AUTOSAR XML (schema 314)
package /ComponentType
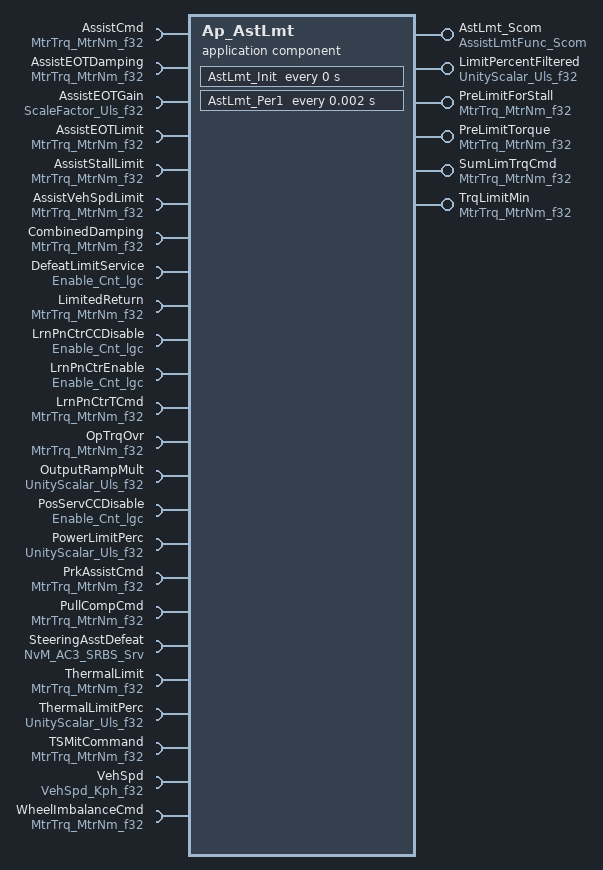
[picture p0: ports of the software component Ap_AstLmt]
  application software component type Ap_AstLmt
    6 x provide port:
      AstLmt_Scom: provided-interface=AssistLmtFunc_Scom
        provided-com-specs:
          operation=GetSteeringAssistDefeat, queue-length=1
          operation=ManualTrqCmd, queue-length=1
          operation=SetSteeringAssistDefeat, queue-length=1
      LimitPercentFiltered: unqueued-sender-com-spec{data-element=Uls_f32, can-invalidate=false, init-value=D_ZERO_ULS_F32}, provided-interface=UnityScalar_Uls_f32
      PreLimitForStall: unqueued-sender-com-spec{data-element=MtrNm_f32, can-invalidate=false, init-value=D_ZERO_ULS_F32}, provided-interface=MtrTrq_MtrNm_f32
      PreLimitTorque: unqueued-sender-com-spec{data-element=MtrNm_f32, can-invalidate=false, init-value=D_ZERO_ULS_F32}, provided-interface=MtrTrq_MtrNm_f32
      SumLimTrqCmd: unqueued-sender-com-spec{data-element=MtrNm_f32, can-invalidate=false, init-value=D_ZERO_ULS_F32}, provided-interface=MtrTrq_MtrNm_f32
      TrqLimitMin: unqueued-sender-com-spec{data-element=MtrNm_f32, can-invalidate=false, init-value=D_ZERO_ULS_F32}, provided-interface=MtrTrq_MtrNm_f32
    24 x require port:
      AssistCmd: unqueued-receiver-com-spec{data-element=MtrNm_f32, init-value=D_ZERO_ULS_F32}, required-interface=MtrTrq_MtrNm_f32
      AssistEOTDamping: unqueued-receiver-com-spec{data-element=MtrNm_f32, init-value=D_ZERO_ULS_F32}, required-interface=MtrTrq_MtrNm_f32
      AssistEOTGain: unqueued-receiver-com-spec{data-element=Uls_f32, init-value=D_ONE_ULS_F32}, required-interface=ScaleFactor_Uls_f32
      AssistEOTLimit: unqueued-receiver-com-spec{data-element=MtrNm_f32, init-value=D_MTRTRQCMDHILMT_MTRNM_F32}, required-interface=MtrTrq_MtrNm_f32
      AssistStallLimit: unqueued-receiver-com-spec{data-element=MtrNm_f32, init-value=D_MTRTRQCMDHILMT_MTRNM_F32}, required-interface=MtrTrq_MtrNm_f32
      AssistVehSpdLimit: unqueued-receiver-com-spec{data-element=MtrNm_f32, init-value=D_MTRTRQCMDHILMT_MTRNM_F32}, required-interface=MtrTrq_MtrNm_f32
      CombinedDamping: unqueued-receiver-com-spec{data-element=MtrNm_f32, init-value=D_ZERO_ULS_F32}, required-interface=MtrTrq_MtrNm_f32
      DefeatLimitService: unqueued-receiver-com-spec{data-element=Cnt_lgc, init-value=D_FALSE_CNT_LGC}, required-interface=Enable_Cnt_lgc
      LimitedReturn: unqueued-receiver-com-spec{data-element=MtrNm_f32, init-value=D_ZERO_ULS_F32}, required-interface=MtrTrq_MtrNm_f32
      LrnPnCtrCCDisable: unqueued-receiver-com-spec{data-element=Cnt_lgc, init-value=D_FALSE_CNT_LGC}, required-interface=Enable_Cnt_lgc
      LrnPnCtrEnable: unqueued-receiver-com-spec{data-element=Cnt_lgc, init-value=D_FALSE_CNT_LGC}, required-interface=Enable_Cnt_lgc
      LrnPnCtrTCmd: unqueued-receiver-com-spec{data-element=MtrNm_f32, init-value=D_ZERO_ULS_F32}, required-interface=MtrTrq_MtrNm_f32
      OpTrqOvr: unqueued-receiver-com-spec{data-element=MtrNm_f32, init-value=D_ZERO_ULS_F32}, required-interface=MtrTrq_MtrNm_f32
      OutputRampMult: unqueued-receiver-com-spec{data-element=Uls_f32, init-value=D_ZERO_ULS_F32}, required-interface=UnityScalar_Uls_f32
      PosServCCDisable: unqueued-receiver-com-spec{data-element=Cnt_lgc, init-value=D_FALSE_CNT_LGC}, required-interface=Enable_Cnt_lgc
      PowerLimitPerc: unqueued-receiver-com-spec{data-element=Uls_f32, init-value=D_ZERO_ULS_F32}, required-interface=UnityScalar_Uls_f32
      PrkAssistCmd: unqueued-receiver-com-spec{data-element=MtrNm_f32, init-value=D_ZERO_ULS_F32}, required-interface=MtrTrq_MtrNm_f32
      PullCompCmd: unqueued-receiver-com-spec{data-element=MtrNm_f32, init-value=D_ZERO_ULS_F32}, required-interface=MtrTrq_MtrNm_f32
      SteeringAsstDefeat: required-com-specs=[EraseBlock, GetErrorStatus, InvalidateNvBlock, ReadBlock, SetRamBlockStatus, WriteBlock], required-interface=NvM_AC3_SRBS_Srv
      ThermalLimit: unqueued-receiver-com-spec{data-element=MtrNm_f32, init-value=D_MTRTRQCMDHILMT_MTRNM_F32}, required-interface=MtrTrq_MtrNm_f32
      ThermalLimitPerc: unqueued-receiver-com-spec{data-element=Uls_f32, init-value=D_ZERO_ULS_F32}, required-interface=UnityScalar_Uls_f32
      TSMitCommand: unqueued-receiver-com-spec{data-element=MtrNm_f32, init-value=D_ZERO_ULS_F32}, required-interface=MtrTrq_MtrNm_f32
      VehSpd: unqueued-receiver-com-spec{data-element=Kph_f32, init-value=D_ZERO_ULS_F32}, required-interface=VehSpd_Kph_f32
      WheelImbalanceCmd: unqueued-receiver-com-spec{data-element=MtrNm_f32, init-value=D_ZERO_ULS_F32}, required-interface=MtrTrq_MtrNm_f32
  internal behavior Ap_AstLmt_InternalBehavior: component=Ap_AstLmt
    timing event AstLmt_InitEvent: start-on-event=AstLmt_Init, period=0
    timing event TMT_AstLmt_Per1: start-on-event=AstLmt_Per1, period=0.002
    operation invoked event OIT_AstLmt_Scom_GetSteeringAssistDefeat_AstLmt_Scom_GetSteeringAssistDefeat: start-on-event=AstLmt_Scom_GetSteeringAssistDefeat, operation=AstLmt_Scom.GetSteeringAssistDefeat
    operation invoked event OIT_AstLmt_Scom_ManualTrqCmd_AstLmt_Scom_ManualTrqCmd: start-on-event=AstLmt_Scom_ManualTrqCmd, operation=AstLmt_Scom.ManualTrqCmd
    operation invoked event OIT_AstLmt_Scom_SetSteeringAssistDefeat_AstLmt_Scom_SetSteeringAssistDefeat: start-on-event=AstLmt_Scom_SetSteeringAssistDefeat, operation=AstLmt_Scom.SetSteeringAssistDefeat
    per instance memory SteerAsstDefeat: type=Boolean, type-definition=/DataType/Boolean
    port-api-options:
      enable-take-address=false, indirect-api=false, port=AssistCmd
      enable-take-address=false, indirect-api=false, port=AssistEOTDamping
      enable-take-address=false, indirect-api=false, port=AssistEOTGain
      enable-take-address=false, indirect-api=false, port=AssistEOTLimit
      enable-take-address=false, indirect-api=false, port=AssistStallLimit
      enable-take-address=false, indirect-api=false, port=AssistVehSpdLimit
      enable-take-address=false, indirect-api=false, port=AstLmt_Scom
      enable-take-address=false, indirect-api=false, port=CombinedDamping
      enable-take-address=false, indirect-api=false, port=DefeatLimitService
      enable-take-address=false, indirect-api=false, port=LimitedReturn
      enable-take-address=false, indirect-api=false, port=LimitPercentFiltered
      enable-take-address=false, indirect-api=false, port=LrnPnCtrCCDisable
      enable-take-address=false, indirect-api=false, port=LrnPnCtrEnable
      enable-take-address=false, indirect-api=false, port=LrnPnCtrTCmd
      enable-take-address=false, indirect-api=false, port=OpTrqOvr
      enable-take-address=false, indirect-api=false, port=OutputRampMult
      enable-take-address=false, indirect-api=false, port=PosServCCDisable
      enable-take-address=false, indirect-api=false, port=PowerLimitPerc
      enable-take-address=false, indirect-api=false, port=PreLimitForStall
      enable-take-address=false, indirect-api=false, port=PreLimitTorque
      enable-take-address=false, indirect-api=false, port=PrkAssistCmd
      enable-take-address=false, indirect-api=false, port=PullCompCmd
      enable-take-address=false, indirect-api=false, port=SteeringAsstDefeat
      enable-take-address=false, indirect-api=false, port=SumLimTrqCmd
      enable-take-address=false, indirect-api=false, port=ThermalLimit
      enable-take-address=false, indirect-api=false, port=ThermalLimitPerc
      enable-take-address=false, indirect-api=false, port=TrqLimitMin
      enable-take-address=false, indirect-api=false, port=TSMitCommand
      enable-take-address=false, indirect-api=false, port=VehSpd
      enable-take-address=false, indirect-api=false, port=WheelImbalanceCmd
    5 x runnable:
      AstLmt_Init
      AstLmt_Per1
        23 x data read access:
          READ_AssistCmd_MtrNm_f32: data-element=AssistCmd.MtrNm_f32
          READ_AssistEOTDamping_MtrNm_f32: data-element=AssistEOTDamping.MtrNm_f32
          READ_AssistEOTGain_Uls_f32: data-element=AssistEOTGain.Uls_f32
          READ_AssistEOTLimit_MtrNm_f32: data-element=AssistEOTLimit.MtrNm_f32
          READ_AssistStallLimit_MtrNm_f32: data-element=AssistStallLimit.MtrNm_f32
          READ_AssistVehSpdLimit_MtrNm_f32: data-element=AssistVehSpdLimit.MtrNm_f32
          READ_CombinedDamping_MtrNm_f32: data-element=CombinedDamping.MtrNm_f32
          READ_DefeatLimitService_Cnt_lgc: data-element=DefeatLimitService.Cnt_lgc
          READ_LimitedReturn_MtrNm_f32: data-element=LimitedReturn.MtrNm_f32
          READ_LrnPnCtrCCDisable_Cnt_lgc: data-element=LrnPnCtrCCDisable.Cnt_lgc
          READ_LrnPnCtrEnable_Cnt_lgc: data-element=LrnPnCtrEnable.Cnt_lgc
          READ_LrnPnCtrTCmd_MtrNm_f32: data-element=LrnPnCtrTCmd.MtrNm_f32
          READ_OpTrqOvr_MtrNm_f32: data-element=OpTrqOvr.MtrNm_f32
          READ_OutputRampMult_Uls_f32: data-element=OutputRampMult.Uls_f32
          READ_PosServCCDisable_Cnt_lgc: data-element=PosServCCDisable.Cnt_lgc
          READ_PowerLimitPerc_Uls_f32: data-element=PowerLimitPerc.Uls_f32
          READ_PrkAssistCmd_MtrNm_f32: data-element=PrkAssistCmd.MtrNm_f32
          READ_PullCompCmd_MtrNm_f32: data-element=PullCompCmd.MtrNm_f32
          READ_ThermalLimit_MtrNm_f32: data-element=ThermalLimit.MtrNm_f32
          READ_ThermalLimitPerc_Uls_f32: data-element=ThermalLimitPerc.Uls_f32
          READ_TSMitCommand_MtrNm_f32: data-element=TSMitCommand.MtrNm_f32
          READ_VehSpd_Kph_f32: data-element=VehSpd.Kph_f32
          READ_WheelImbalanceCmd_MtrNm_f32: data-element=WheelImbalanceCmd.MtrNm_f32
        5 x data write access:
          WRITE_LimitPercentFiltered_Uls_f32: data-element=LimitPercentFiltered.Uls_f32
          WRITE_PreLimitForStall_MtrNm_f32: data-element=PreLimitForStall.MtrNm_f32
          WRITE_PreLimitTorque_MtrNm_f32: data-element=PreLimitTorque.MtrNm_f32
          WRITE_SumLimTrqCmd_MtrNm_f32: data-element=SumLimTrqCmd.MtrNm_f32
          WRITE_TrqLimitMin_MtrNm_f32: data-element=TrqLimitMin.MtrNm_f32
      AstLmt_Scom_GetSteeringAssistDefeat
      AstLmt_Scom_ManualTrqCmd: can-be-invoked-concurrently=true
        data receive point REC_VehSpd_Kph_f32: data-element=VehSpd.Kph_f32
      AstLmt_Scom_SetSteeringAssistDefeat
        sync call SC_SteeringAsstDefeat_WriteBlock: operation=SteeringAsstDefeat.WriteBlock, timeout=0
    service-needss:
      swc nv block needs SteeringAsstDefeat: n-data-sets=0, readonly=false, reliability=LOW, resistant-to-changed-sw=false, restore-at-start=false, write-only-once=false, writing-frequency=0, writing-priority=LOW, mirror-block=SteerAsstDefeat
  swc implementation Ap_AstLmt_Implementation: behavior=Ap_AstLmt_InternalBehavior
    code-descriptors:
      code Code: type=SRC
